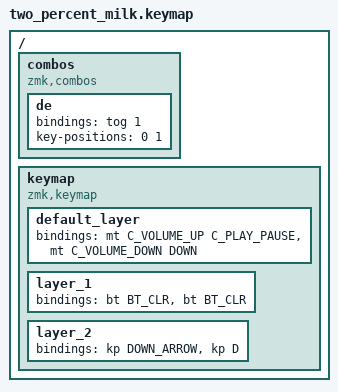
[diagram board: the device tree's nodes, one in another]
/*
 * Copyright (c) 2022 The ZMK Contributors
 *
 * SPDX-License-Identifier: MIT
 */

#include <behaviors.dtsi>
#include <dt-bindings/zmk/bt.h>
#include <dt-bindings/zmk/keys.h>

/ {
    combos {
        compatible = "zmk,combos";

        de {
            bindings = <&tog 1>;
            key-positions = <0 1>;
        };
    };

    keymap {
        compatible = "zmk,keymap";

        default_layer {
            bindings = <
&mt C_VOLUME_UP C_PLAY_PAUSE  &mt C_VOLUME_DOWN DOWN
            >;
        };

        layer_1 {
            bindings = <
&bt BT_CLR  &bt BT_CLR
            >;
        };

        layer_2 {
            bindings = <
&kp DOWN_ARROW  &kp D
            >;
        };
    };
};
